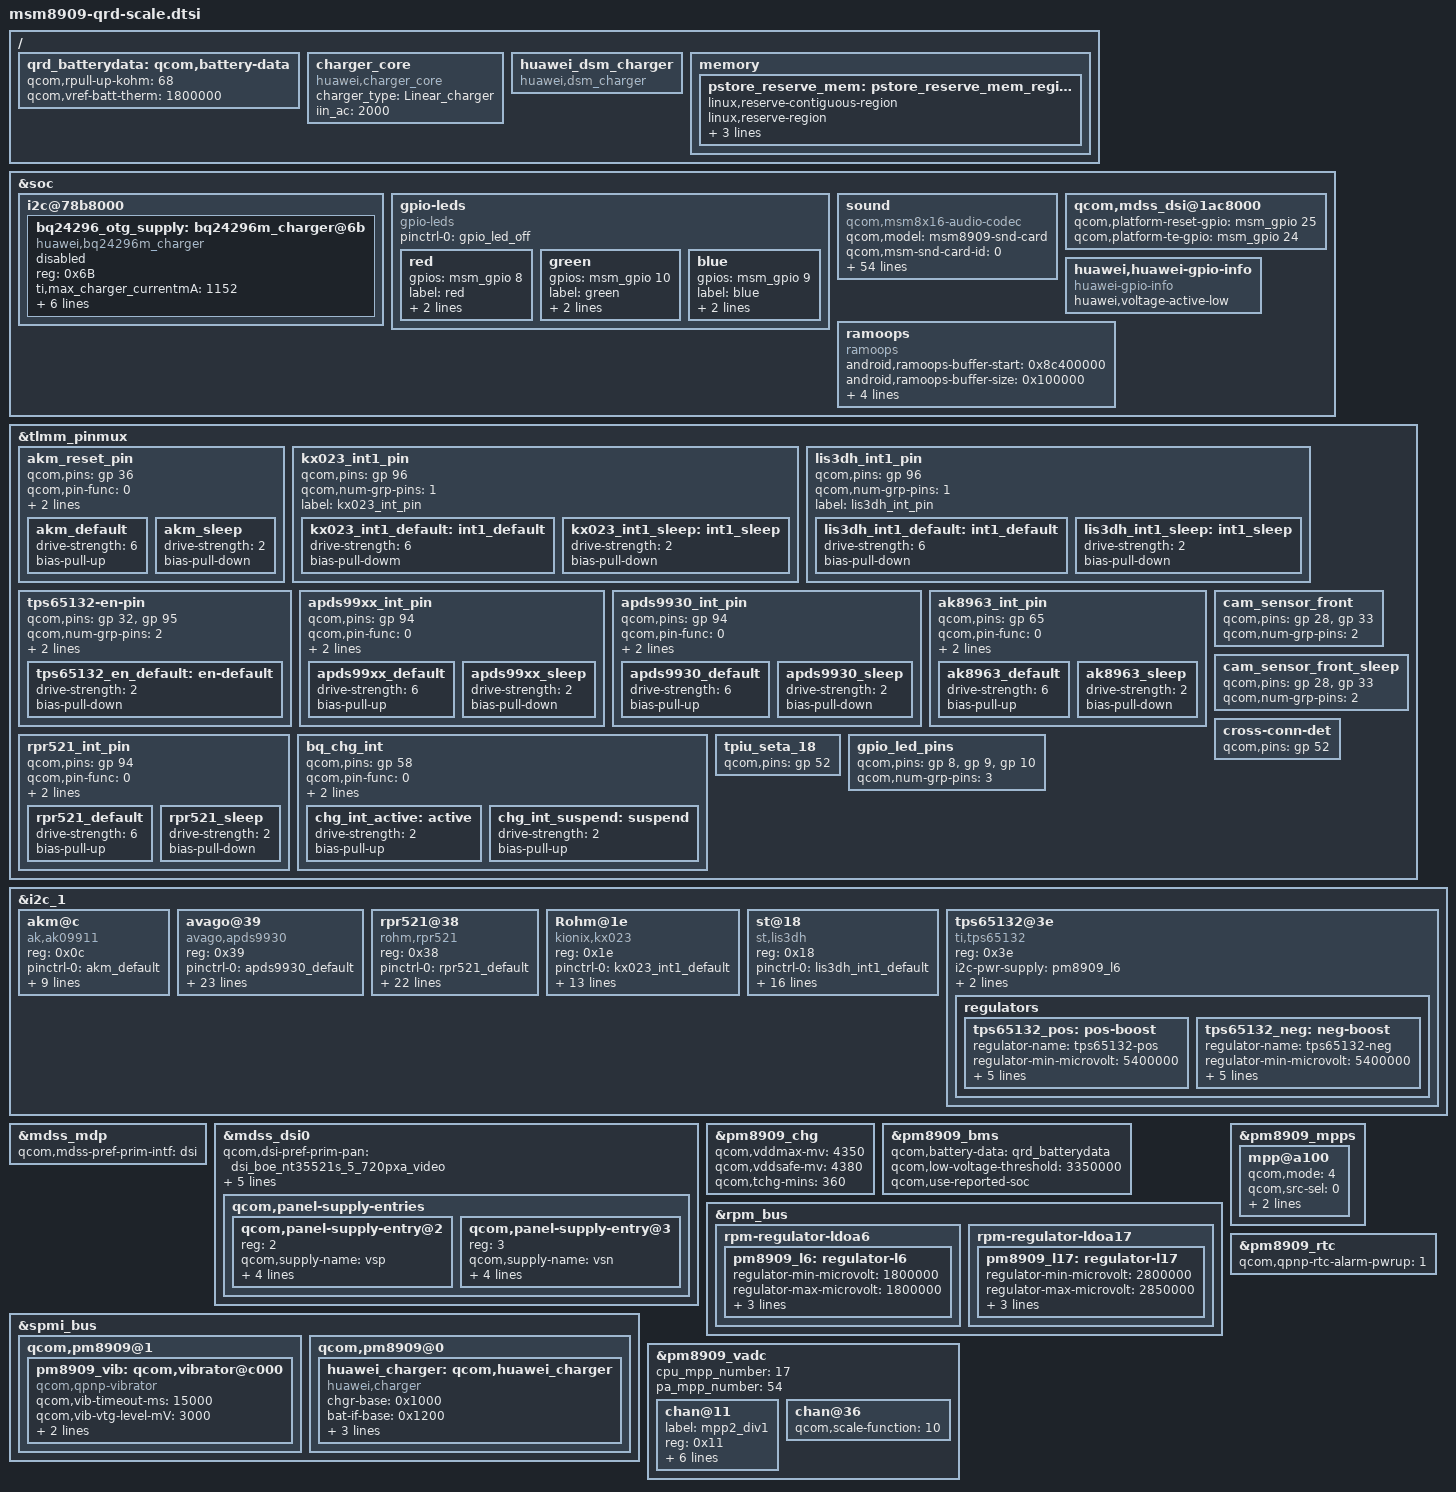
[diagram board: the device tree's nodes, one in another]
/* Copyright (c) 2014, The Linux Foundation. All rights reserved.
 *
 * This program is free software; you can redistribute it and/or modify
 * it under the terms of the GNU General Public License version 2 and
 * only version 2 as published by the Free Software Foundation.
 *
 * This program is distributed in the hope that it will be useful,
 * but WITHOUT ANY WARRANTY; without even the implied warranty of
 * MERCHANTABILITY or FITNESS FOR A PARTICULAR PURPOSE.  See the
 * GNU General Public License for more details.
 */

#include "../boe-nt35521s-5-720p-video.dtsi"
#include "hw-panel-boe-nt35521-5-720pxa-video.dtsi"
#include "hw-panel-boe-nt35521s-5-720pxa-video.dtsi"
#include "hw-panel-boe-otm1284a-5-720pxa-video.dtsi"
#include "hw-panel-cmi-nt35521s-5-720pxa-video.dtsi"
#include "hw-panel-cmi-otm1283a-5-720pxa-video.dtsi"
#include "hw-panel-tianma-otm1287a-5-720pxa-video.dtsi"
#include "msm8909-camera-sensor-qrd-scale.dtsi"
#include "huawei-tp.dtsi"

&soc {
	i2c@78b8000{ /* BLSP1 QUP6 */
		bq24296_otg_supply: bq24296m_charger@6b {
		compatible = "huawei,bq24296m_charger";
		reg = <0x6B>;
		ti,max_charger_currentmA = <1152>;
		ti,max_charger_voltagemV = <4350>;
		ti,max_cin_limit_currentmA = <1500>;
		gpio_int = <&msm_gpio 58 0x00>;
		pinctrl-names = "bq_active","bq_suspend";
		pinctrl-0 = <&chg_int_active>;
		pinctrl-1 = <&chg_int_suspend>;
		regulator-name = "bq24296_otg_vreg";
		status = "disabled";
		};
	};
};

&tlmm_pinmux {
	akm_reset_pin {
		qcom,pins = <&gp 36>;
		qcom,pin-func = <0>;
		qcom,num-grp-pins = <1>;
		label = "akm_reset_pin";
		akm_default: akm_default {
			drive-strength = <6>;
			bias-pull-up;
		};
		akm_sleep: akm_sleep {
			drive-strength = <2>;
			bias-pull-down;
		};
	};

	kx023_int1_pin {
		qcom,pins = <&gp 96>;
		qcom,num-grp-pins = <1>;
		label = "kx023_int_pin";
		kx023_int1_default: int1_default {
			drive-strength = <6>;
			bias-pull-dowm;
		};
		kx023_int1_sleep: int1_sleep {
			drive-strength = <2>;
			bias-pull-down;
		};
	};

	lis3dh_int1_pin {
		qcom,pins = <&gp 96>;
		qcom,num-grp-pins = <1>;
		label = "lis3dh_int_pin";
		lis3dh_int1_default: int1_default {
			drive-strength = <6>;
			bias-pull-down;
		};
		lis3dh_int1_sleep: int1_sleep {
			drive-strength = <2>;
			bias-pull-down;
		};
	};

	tps65132-en-pin {
		qcom,pins = <&gp 32>, <&gp 95>;
		qcom,num-grp-pins = <2>;
		label = "tps65132_en_pins";
		qcom,pin-func = <0>;

		tps65132_en_default: en-default {
			drive-strength = <2>;
			bias-pull-down;
		};
	};

	apds99xx_int_pin {
		qcom,pins = <&gp 94>;
		qcom,pin-func = <0>;
		qcom,num-grp-pins = <1>;
		label = "apds99xx-irq";
		apds99xx_default: apds99xx_default {
			drive-strength = <6>;
			bias-pull-up;
		};
		apds99xx_sleep: apds99xx_sleep {
			drive-strength = <2>;
			bias-pull-down;
		};
	};

	apds9930_int_pin {
		qcom,pins = <&gp 94>;
		qcom,pin-func = <0>;
		qcom,num-grp-pins = <1>;
		label = "apds9930-irq";
		apds9930_default: apds9930_default {
			drive-strength = <6>;
			bias-pull-up;
		};
		apds9930_sleep: apds9930_sleep {
			drive-strength = <2>;
			bias-pull-down;
		};
	};

	ak8963_int_pin {
		qcom,pins = <&gp 65>;
		qcom,pin-func = <0>;
		qcom,num-grp-pins = <1>;
		label = "ak8963-irq";
		ak8963_default: ak8963_default {
			drive-strength = <6>;
			bias-pull-up;
		};
		ak8963_sleep: ak8963_sleep {
			drive-strength = <2>;
			bias-pull-down;
		};
	};

	rpr521_int_pin {
		qcom,pins = <&gp 94>;
		qcom,pin-func = <0>;
		qcom,num-grp-pins = <1>;
		label = "rpr521-irq";
		rpr521_default: rpr521_default {
			drive-strength = <6>;
			bias-pull-up;
		};
		rpr521_sleep: rpr521_sleep {
			drive-strength = <2>;
			bias-pull-down;
		};
	};

	bq_chg_int{
		qcom,pins = <&gp 58>;
		qcom,pin-func = <0>;
		qcom,num-grp-pins = <1>;
		label = "bq_chg_int";
		chg_int_active: active {
			drive-strength = <2>;
			bias-pull-up;
		};
		chg_int_suspend: suspend {
			drive-strength = <2>;
			bias-pull-up;
		};
	};

	/* pins override */

	cam_sensor_front {
		qcom,pins = <&gp 28>, <&gp 33>;
		qcom,num-grp-pins = <2>;
	};

	cam_sensor_front_sleep {
		qcom,pins = <&gp 28>, <&gp 33>;
		qcom,num-grp-pins = <2>;
	};

	cross-conn-det {
		qcom,pins = <&gp 52>;
	};

	tpiu_seta_18 {
		qcom,pins = <&gp 52>;
	};

	gpio_led_pins {
		qcom,pins = <&gp 8>, <&gp 9>, <&gp 10>;
		qcom,num-grp-pins = <3>;
	};

};

&i2c_1 { /* BLSP1 QUP1 */
	akm@c {
		compatible = "ak,ak09911";
		reg = <0x0c>;
		pinctrl-names = "default","sleep";
		pinctrl-0 = <&akm_default>;
		pinctrl-1 = <&akm_sleep>;
		vdd-supply = <&pm8909_l17>;
		vio-supply = <&pm8909_l6>;
		akm,layout = <0x6>;
		akm,gpio_rstn = <&msm_gpio 36 0x0>;
		akm,auto-report;
		akm,pdc_file_name = "pdc_scale_al00.txt";
		akm,i2c-scl-gpio = <&msm_gpio 7 0x0>;
		akm,i2c-sda-gpio = <&msm_gpio 6 0x0>;
	};

	avago@39 {
		compatible = "avago,apds9930";
		reg = <0x39>;
		pinctrl-names = "default","sleep";
		pinctrl-0 = <&apds9930_default>;
		pinctrl-1 = <&apds9930_sleep>;
		interrupt-parent = <&msm_gpio>;
		interrupts = <94 0x2002>;
		vdd-supply = <&pm8909_l17>;
		vio-supply = <&pm8909_l6>;
		avago,irq-gpio = <&msm_gpio 94 0x2002>;
		avago,ps-threshold = <600>;
		avago,ps-hysteresis-threshold = <500>;
		avago,ps-pulse = <8>;
		avago,ps-pgain = <0>;
		avago,als-B = <186>;
		avago,als-C = <75>;
		avago,als-D = <129>;
		avago,ga-value = <48>;
		avago,ga-a-value = <200>;
		avago,ga-c-value = <600>;
		avago,ga-d-value = <180>;
		avago,window = <95>;
		avago,wave = <50>;
		avago,ga-e-value = <210>;
		avago,ga-f-value = <50>;
		avago,i2c-scl-gpio = <&msm_gpio 7 0x0>;
		avago,i2c-sda-gpio = <&msm_gpio 6 0x0>;
	};

	rpr521@38 {
		compatible = "rohm,rpr521";
		reg = <0x38>;
		pinctrl-names = "default","sleep";
		pinctrl-0 = <&rpr521_default>;
		pinctrl-1 = <&rpr521_sleep>;
		interrupt-parent = <&msm_gpio>;
		interrupts = <94 0x2002>;
		vdd-supply = <&pm8909_l17>;
		vio-supply = <&pm8909_l6>;
		rpr521,irq-gpio = <&msm_gpio 94 0x2002>;
		rpr521,ps_threshold = <600>;
		rpr521,window = <102>;
		rpr521,wave = <70>;
		rpr521,ps_gain = <4>;
		rpr521,diff_tp = <1>;
		rpr521,data0_array = <7562 3766 2756 1810>;
		rpr521,data1_array = <5220 1926 1232 580>;
		rpr521,judge_array = <900 1350 2416 3100>;
		//junda
		rpr521,data0_array_ju = <11967 6069 4129 1810>;
		rpr521,data1_array_ju = <6974 2976 1640 580>;
		rpr521,judge_array_ju = <900 1580 2416 3100>;
		//ofilm
		rpr521,data0_array_of = <11081 4638 3010 1810>;
		rpr521,data1_array_of = <7210 2276 1221 580>;
		rpr521,judge_array_of = <900 1480 2416 3100>;
		rpr521,i2c-scl-gpio = <&msm_gpio 7 0x0>;
		rpr521,i2c-sda-gpio = <&msm_gpio 6 0x0>;
	};

	Rohm@1e {
		compatible = "kionix,kx023";
		reg = <0x1e>;
		pinctrl-names = "kx023_default","kx023_sleep";
		pinctrl-0 = <&kx023_int1_default>;
		pinctrl-1 = <&kx023_int1_sleep>;
		vdd-supply = <&pm8909_l17>;
		vddio-supply = <&pm8909_l6>;
		gs,int1_gpio = <&msm_gpio 96 0x2002>;
		/*1 is bottom and others means top*/
                gs,direct = <0>;
		gs,min_interval = <5>;
		gs,poll_interval = <200>;
		gs,accel_direction = <1>;
		gs,accel_irq_use_drdy = <0>;
		gs,accel_g_range = <0>;
		gs,accel_res = <0>;
		gs,i2c-scl-gpio = <&msm_gpio 7 0x0>;
		gs,i2c-sda-gpio = <&msm_gpio 6 0x0>;
	};

	st@18 {
		compatible = "st,lis3dh";
		reg = <0x18>;
		pinctrl-names = "lis3dh_default","lis3dh_sleep";
		pinctrl-0 = <&lis3dh_int1_default>;
		pinctrl-1 = <&lis3dh_int1_sleep>;
		interrupt-parent = <&msm_gpio>;
		vdd-supply = <&pm8909_l17>;
		vddio-supply = <&pm8909_l6>;
		st,min-interval = <5>;
		st,init-interval = <200>;
		st,axis-map-x = <0>;
		st,axis-map-y = <1>;
		st,axis-map-z = <2>;
		/*1 is bottom and others means top*/
                st,axis-map-bottom=<0>;
		st,g-range = <2>;
		st,gpio-int1 = <&msm_gpio 96 0x2002>;
		/delete-property/st,negate-x;
		st,negate-z;
		st,negate-y;
		st,i2c-scl-gpio = <&msm_gpio 7 0x0>;
		st,i2c-sda-gpio = <&msm_gpio 6 0x0>;
	};

	tps65132@3e {
		compatible = "ti,tps65132";
		reg = <0x3e>;
		i2c-pwr-supply = <&pm8909_l6>;
		ti,en-gpio-lpm;
		pinctrl-names = "default";
		pinctrl-0 = <&tps65132_en_default>;

		regulators {
			tps65132_pos: pos-boost {
				regulator-name = "tps65132-pos";
				regulator-min-microvolt = <5400000>;
				regulator-max-microvolt = <5400000>;
				ti,discharge-enable;
				ti,enable-time = <800>;
				ti,current-limit = <200000>;
				ti,en-gpio = <&msm_gpio 95 0>;
			};

			tps65132_neg: neg-boost {
				regulator-name = "tps65132-neg";
				regulator-min-microvolt = <5400000>;
				regulator-max-microvolt = <5400000>;
				ti,discharge-enable;
				ti,enable-time = <800>;
				ti,current-limit = <40000>;
				ti,en-gpio = <&msm_gpio 32 0>;
			};
		};
	};

};

&mdss_mdp {
	qcom,mdss-pref-prim-intf = "dsi";
};

&mdss_dsi0 {
	qcom,dsi-pref-prim-pan = <&dsi_boe_nt35521s_5_720pxa_video>;
	pinctrl-names = "mdss_default", "mdss_sleep";
	pinctrl-0 = <&mdss_dsi_active &mdss_te_active>;
	pinctrl-1 = <&mdss_dsi_suspend &mdss_te_suspend>;

	qcom,platform-reset-gpio = <&msm_gpio 25 0>;

	vsp-supply = <&tps65132_pos>;
	vsn-supply = <&tps65132_neg>;
	qcom,panel-supply-entries {
		#address-cells = <1>;
		#size-cells = <0>;

		qcom,panel-supply-entry@2 {
			reg = <2>;
			qcom,supply-name = "vsp";
			qcom,supply-min-voltage = <5400000>;
			qcom,supply-max-voltage = <5400000>;
			qcom,supply-enable-load = <200>;
			qcom,supply-disable-load = <0>;
		};

		qcom,panel-supply-entry@3 {
			reg = <3>;
			qcom,supply-name = "vsn";
			qcom,supply-min-voltage = <5400000>;
			qcom,supply-max-voltage = <5400000>;
			qcom,supply-enable-load = <40>;
			qcom,supply-disable-load = <0>;
		};
	};
};

&soc {
	gpio-leds {
		compatible = "gpio-leds";
		status = "okay";
		pinctrl-names = "default";
		pinctrl-0 = <&gpio_led_off>;

		red {
			gpios = <&msm_gpio 8 0>;
			label = "red";
			linux,default-trigger = "none";
			default-state = "off";
		};

		green {
			gpios = <&msm_gpio 10 0>;
			label = "green";
			linux,default-trigger = "none";
			default-state = "off";
		};

		blue {
			gpios = <&msm_gpio 9 0>;
			label = "blue";
			linux,default-trigger = "none";
			default-state = "off";
		};
	};

	sound {
			compatible = "qcom,msm8x16-audio-codec";
			qcom,model = "msm8909-snd-card";
			qcom,msm-snd-card-id = <0>;
			qcom,msm-ext-pa = "primary";
			qcom,msm-codec-type = "internal";
			qcom,msm-mclk-freq = <9600000>;
			qcom,msm-mbhc-hphl-swh = <1>;
			qcom,msm-mbhc-gnd-swh = <0>;
			qcom,msm-hs-micbias-type = "external";
			qcom,msm-micbias1-ext-cap;
			qcom,msm-micbias2-ext-cap;
			qcom,audio-routing =
				"RX_BIAS", "MCLK",
				"SPK_RX_BIAS", "MCLK",
				"INT_LDO_H", "MCLK",
				"MIC BIAS External", "Handset Mic",
				"MIC BIAS External2", "Headset Mic",
				"MIC BIAS External", "Secondary Mic",
				"AMIC1", "MIC BIAS External",
				"AMIC2", "MIC BIAS External2",
				"AMIC3", "MIC BIAS External";
			pinctrl-names = "cdc_lines_act",
					"cdc_lines_sus",
					"cross_conn_det_act",
					"cross_conn_det_sus";
			pinctrl-0 = <&cdc_pdm_lines_act>;
			pinctrl-1 = <&cdc_pdm_lines_sus>;
			pinctrl-2 = <&cross_conn_det_act>;
			pinctrl-3 = <&cross_conn_det_sus>;
			asoc-platform = <&pcm0>, <&pcm1>, <&voip>, <&voice>,
					<&loopback>, <&compress>, <&hostless>,
					<&afe>, <&lsm>, <&routing>, <&lpa>,
					<&voice_svc>;
			asoc-platform-names = "msm-pcm-dsp.0", "msm-pcm-dsp.1",
					"msm-voip-dsp", "msm-pcm-voice", "msm-pcm-loopback",
					"msm-compress-dsp", "msm-pcm-hostless", "msm-pcm-afe",
					"msm-lsm-client", "msm-pcm-routing", "msm-pcm-lpa",
					"msm-voice-svc";
			asoc-cpu = <&dai_pri_auxpcm>, <&dai_hdmi>,
					<&dai_mi2s0>, <&dai_mi2s1>, <&dai_mi2s2>, <&dai_mi2s3>,
					<&sb_0_rx>, <&sb_0_tx>, <&sb_1_rx>, <&sb_1_tx>,
					<&sb_3_rx>, <&sb_3_tx>, <&sb_4_rx>, <&sb_4_tx>,
					<&bt_sco_rx>, <&bt_sco_tx>, <&bt_a2dp_rx>,
					<&int_fm_rx>, <&int_fm_tx>,
					<&afe_pcm_rx>, <&afe_pcm_tx>, <&afe_proxy_rx>,
					<&afe_proxy_tx>, <&incall_record_rx>,
					<&incall_record_tx>, <&incall_music_rx>,
					<&incall_music_2_rx>;
			asoc-cpu-names = "msm-dai-q6-auxpcm.1", "msm-dai-q6-hdmi.8",
					"msm-dai-q6-mi2s.0", "msm-dai-q6-mi2s.1",
					"msm-dai-q6-mi2s.2", "msm-dai-q6-mi2s.3",
					"msm-dai-q6-dev.16384", "msm-dai-q6-dev.16385",
					"msm-dai-q6-dev.16386", "msm-dai-q6-dev.16387",
					"msm-dai-q6-dev.16390", "msm-dai-q6-dev.16391",
					"msm-dai-q6-dev.16392", "msm-dai-q6-dev.16393",
					"msm-dai-q6-dev.12288", "msm-dai-q6-dev.12289",
					"msm-dai-q6-dev.12290", "msm-dai-q6-dev.12292",
					"msm-dai-q6-dev.12293",	"msm-dai-q6-dev.224",
					"msm-dai-q6-dev.225", "msm-dai-q6-dev.241",
					"msm-dai-q6-dev.240", "msm-dai-q6-dev.32771",
					"msm-dai-q6-dev.32772", "msm-dai-q6-dev.32773",
					"msm-dai-q6-dev.32770";
			asoc-codec = <&stub_codec>, <&pm8909_conga_dig>;
			asoc-codec-names = "msm-stub-codec.1", "tombak_codec";
	};

	qcom,mdss_dsi@1ac8000 {
		qcom,platform-reset-gpio = <&msm_gpio 25 0>;
		qcom,platform-te-gpio = <&msm_gpio 24 0>;
	};
};

&pm8909_chg {
	qcom,vddmax-mv = <4350>;
	qcom,vddsafe-mv = <4380>;
	qcom,tchg-mins = <360>;
	status = "okay";
};

/ {
	qrd_batterydata: qcom,battery-data {
		qcom,rpull-up-kohm = <68>;
		qcom,vref-batt-therm = <1800000>;

                #include "HB3742A0EBC+_ATL_SCUD-4v35-2200mah.dtsi"
                #include "HB3742A0EBC+_SDI_XWD-4v35-2200mah.dtsi"
	};
};

&pm8909_bms {
	status = "ok";
	qcom,battery-data = <&qrd_batterydata>;
	qcom,low-voltage-threshold = <3350000>;
	qcom,use-reported-soc;
};



&rpm_bus {
	rpm-regulator-ldoa6 {
		status = "okay";
		pm8909_l6: regulator-l6 {
			status = "okay";
			regulator-min-microvolt = <1800000>;
			regulator-max-microvolt = <1800000>;
			qcom,init-voltage = <1800000>;
			regulator-boot-on;
			regulator-always-on;
		};
	};

	rpm-regulator-ldoa17 {
		status = "okay";
		pm8909_l17: regulator-l17 {
			status = "okay";
			regulator-min-microvolt = <2800000>;
			regulator-max-microvolt = <2850000>;
			qcom,init-voltage = <2800000>;
			regulator-boot-on;
			regulator-always-on;
		};
	};
};

&spmi_bus{
	qcom,pm8909@1 {
		pm8909_vib: qcom,vibrator@c000 {
		compatible = "qcom,qpnp-vibrator";
		qcom,vib-timeout-ms = <15000>;
		qcom,vib-vtg-level-mV = <3000>;
		reg = <0xc000 0x100>;
		label = "vibrator";
		status = "ok";
		};
	};
};

&pm8909_mpps {
	mpp@a100 {
		qcom,mode = <4>; // QPNP_PIN_MODE_AIN
		qcom,src-sel = <0>; // QPNP_PIN_SEL_FUNC_CONSTANT
		qcom,ain-route = <1>; // QPNP_PIN_AIN_AMUX_CH8
		qcom,master-en = <1>; // Enable features
	};
};

&pm8909_vadc {
	cpu_mpp_number = <17>;
	pa_mpp_number = <54>;

	chan@11 {
		label = "mpp2_div1";
		reg = <0x11>;
		qcom,decimation = <0>; //512 sampling rate
		qcom,pre-div-channel-scaling = <0>; //1:1 scaling
		qcom,calibration-type = "absolute"; //Use 625mV & 1.25V reference voltage
		qcom,scale-function = <10>; //convert raw adc code to voltage
		qcom,hw-settle-time = <2>; //200us
		qcom,fast-avg-setup = <0>; //with only one average measurement
	};

	chan@36 {
		qcom,scale-function = <10>;
	};
};

/{
	charger_core: charger_core{
		compatible = "huawei,charger_core";
		charger_type = "Linear_charger";
		iin_ac = <2000>;
		status = "ok";
	};
};

&spmi_bus{
	qcom,pm8909@0 {
		huawei_charger: qcom,huawei_charger{
			compatible = "huawei,charger";
			chgr-base = <0x1000>;
			bat-if-base = <0x1200>;
			usb-chgpth-base = <0x1300>;
			misc-base = <0x1600>;
			bms-base = <0x4000>;
			status = "ok";
		};
	};
};

&pm8909_rtc{
	qcom,qpnp-rtc-alarm-pwrup = <1>;
};

/{
	huawei_dsm_charger: huawei_dsm_charger{
		compatible = "huawei,dsm_charger";
		status = "ok";
	};
};

/ {
	memory {
		pstore_reserve_mem: pstore_reserve_mem_region@0 {
			linux,reserve-contiguous-region;
			linux,reserve-region;
			linux,remove-completely;
			reg = <0x0 0x8c400000 0x0 0x00100000>;
			label = "pstore_reserve_mem";
		};
	};
};

&soc {

	huawei,huawei-gpio-info {
		compatible = "huawei-gpio-info";
		huawei,voltage-active-low;
	};

	ramoops {
		compatible = "ramoops";
		status = "ok";

		android,ramoops-buffer-start = <0x8c400000>;
		android,ramoops-buffer-size = <0x100000>;
		android,ramoops-console-size = <0x80000>;
		android,ramoops-record-size = <0x7F800>;
		android,ramoops-annotate-size = <0x800>;
		android,ramoops-dump-oops = <0x1>;
	};
};
